# MCU_NAVSS0_UDMASS_RINGACC0_CFG register map
Vendor: Texas Instruments
Peripheral module from a debugger description file (folder am65x).
Registers are 32-bit, read-write, reset 0x0 unless marked. A register's access mark holds for its fields unless they carry their own. Offsets are as the file gives them; lines under a group give offsets from that group; [hi:lo] are bit positions; {n}, {i} and the like mark numbered series; 'fields as' and 'values as' point back to an identical list; <NAME> marks a mode.

## MCU_NAVSS0_UDMASS_RINGACC0_CFG
0x40 RINGACC_BA_LO_J — The Tx Ring Base Address Lo Register contains the 32 LSBs of the base address for the ring which is used to hand off pending work for the channel from the Host. The base address must be aligned to the element size of the ring, or to double the element size of the ring if the qmode is CREDENTIALS or QM modes. A write to this register will reset the associated ring to clear the occupancies and reset the pointers. Offset = 40h + (j * 100h); where j = 0h to 331h for NAVSS0_UDMASS_RINGACC0_CFG j = 0h to 11Dh for MCU_NAVSS0_UDMASS_RINGACC0_CFG
  [31:0] ADDR_LO — Tx Ring base address (LSBs)
0x44 RINGACC_BA_HI_j — The Tx Ring Base Address Hi Register contains the 16 MSBs of the base address for the ring which is used to hand off pending work for the channel from the Host. The base address must be aligned to the element size of the ring, or to double the element size of the ring if the qmode is CREDENTIALS or QM modes. A write to this register will reset the associated ring to clear the occupancies and reset the pointers. Offset = 44h + (j * 100h); where j = 0h to 331h for NAVSS0_UDMASS_RINGACC0_CFG j = 0h to 11Dh for MCU_NAVSS0_UDMASS_RINGACC0_CFG
  [15:0] ADDR_HI — Tx Ring base address (MSBs)
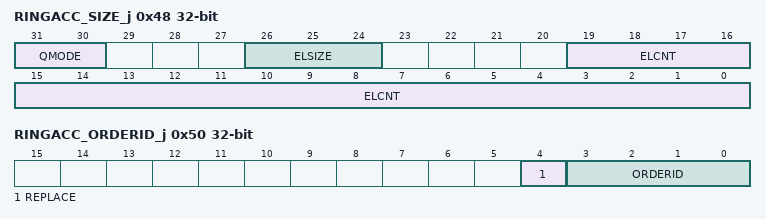
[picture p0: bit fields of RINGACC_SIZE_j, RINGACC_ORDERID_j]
0x48 RINGACC_SIZE_j — The Tx Ring Size Register contains the element size and element counts for the ring which is used to hand off pending work for the channel from the Host. A write to this register will reset the associated ring to clear the occupancies and reset the pointers. Offset = 48h + (j * 100h); where j = 0h to 331h for NAVSS0_UDMASS_RINGACC0_CFG j = 0h to 11Dh for MCU_NAVSS0_UDMASS_RINGACC0_CFG
  [31:30] QMODE — Defines the mode for this ring or queue. 0h = exposed ring mode for SW direct access 1h = messaging mode when all operations are through bus accesses, allowing multiple producers or consumers. 2h = credentials mode is message mode plus stores credentials with each message, requiring the ring size to be doubled to fit the credentials along with the same number of elements when using the first 2 modes. Any exposed memory should be protected by a firewall from unwanted access. 3h = QM mode where the elements include additional fields that the QM supported above messaging credentials mode. Must be used with 8 byte element size only. NOT SUPPORTED.
  [26:24] ELSIZE — Ring element size. This field is encoded as follows: 0 = 4 bytes 1 = 8 bytes 2 = 16 bytes 3 = 32 bytes 4 = 64 bytes 5 = 128 bytes 6 = 256 bytes 7 = RESERVED
  [19:0] ELCNT — Tx Ring element count. This field configures the size of the ring in elements. For rings in CREDENTIALS or QM modes the size must be an even number.
0x4C RINGACC_EVENT_j reset 0xFFFF — The Ring Event Register contains the event number for the ring for when it is active or empty. Offset = 4Ch + (j * 100h); where j = 0h to 331h for NAVSS0_UDMASS_RINGACC0_CFG j = 0h to 11Dh for MCU_NAVSS0_UDMASS_RINGACC0_CFG
  [15:0] EVENT — Defines the event for this ring or queue.
0x50 RINGACC_ORDERID_j — The Ring OrderID Register contains the bus orderid value for the ring memory access. Offset = 50h + (j * 100h); where j = 0h to 331h for NAVSS0_UDMASS_RINGACC0_CFG j = 0h to 11Dh for MCU_NAVSS0_UDMASS_RINGACC0_CFG
  [4] REPLACE — Indicates to replace the bus orderid value for this ring or queue with the orderid MMR field. This allows control over the orderid value when it must be restricted due to the topology for QoS reasons. 0 = bypass and use the orderid from the source transaction for the destination transaction. 1 = use the orderid MMR field value for the destination transaction.
  [3:0] ORDERID — Defines the bus orderid value for this ring or queue.
